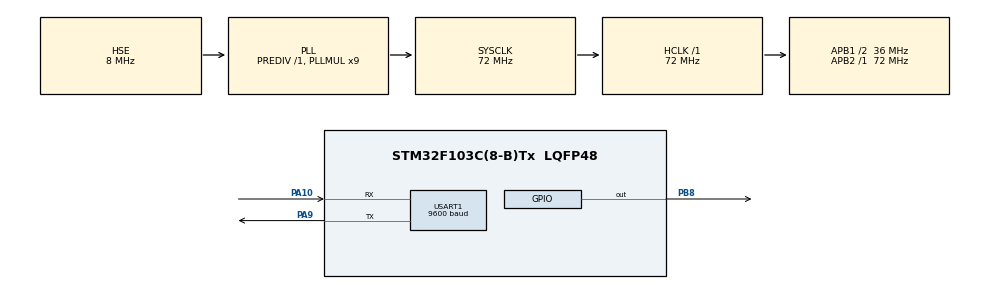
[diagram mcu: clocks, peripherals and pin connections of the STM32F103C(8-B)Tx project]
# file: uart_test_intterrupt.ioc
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Mcu.Family=STM32F1
Mcu.Name=STM32F103C(8-B)Tx
Mcu.Package=LQFP48
NVIC.PriorityGroup=NVIC_PRIORITYGROUP_4
NVIC.USART1_IRQn=true\:0\:0\:false\:false\:true\:true\:true\:true
PA10.Mode=Asynchronous
PA10.Signal=USART1_RX
PA9.Mode=Asynchronous
PA9.Signal=USART1_TX
PB8.PinState=GPIO_PIN_SET
PB8.Signal=GPIO_Output
PD0-OSC_IN.Mode=HSE-External-Oscillator
PD0-OSC_IN.Signal=RCC_OSC_IN
PD1-OSC_OUT.Mode=HSE-External-Oscillator
PD1-OSC_OUT.Signal=RCC_OSC_OUT
ProjectManager.HeapSize=0x200
ProjectManager.StackSize=0x400
ProjectManager.TargetToolchain=MDK-ARM V5.32
RCC.AHBFreq_Value=72000000
RCC.APB1CLKDivider=RCC_HCLK_DIV2
RCC.APB1Freq_Value=36000000
RCC.APB1TimFreq_Value=72000000
RCC.APB2Freq_Value=72000000
RCC.APB2TimFreq_Value=72000000
RCC.HCLKFreq_Value=72000000
RCC.PLLMUL=RCC_PLL_MUL9
RCC.PLLSourceVirtual=RCC_PLLSOURCE_HSE
RCC.SYSCLKFreq_VALUE=72000000
RCC.SYSCLKSource=RCC_SYSCLKSOURCE_PLLCLK
RCC.USBFreq_Value=72000000
USART1.BaudRate=9600
USART1.VirtualMode=VM_ASYNC
VP_SYS_VS_ND.Mode=No_Debug
board=custom

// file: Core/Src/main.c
/* USER CODE BEGIN Header */
/**
  ******************************************************************************
  * @file           : main.c
  * @brief          : Main program body
  ******************************************************************************
  * @attention
  *
  * Copyright (c) 2023 STMicroelectronics.
  * All rights reserved.
  *
  * This software is licensed under terms that can be found in the LICENSE file
  * in the root directory of this software component.
  * If no LICENSE file comes with this software, it is provided AS-IS.
  *
  ******************************************************************************
  */
/* USER CODE END Header */
#include "main.h"
#include "usart.h"
#include "gpio.h"

/* USER CODE BEGIN Includes */
#include <string.h>
#include <stdio.h>
/* USER CODE END Includes */

/* USER CODE BEGIN PM */
//定义最大接收字节数 200，可根据需求调整
#define UART1_REC_LEN 200
/* USER CODE END PM */

/* USER CODE BEGIN PV */
uint16_t UART1_RX_STA=0;
uint8_t buf=0;
// 接收缓冲, 串口接收到的数据放在这个数组里，最大UART1_REC_LEN个字节
uint8_t UART1_RX_Buffer[UART1_REC_LEN];
/* USER CODE END PV */

void SystemClock_Config(void);
/* USER CODE BEGIN PFP */

// 接收中断
void HAL_UART_RxCpltCallback(UART_HandleTypeDef *huart) {
	if(huart->Instance != USART1) {
		return;
	}
	// 数据接收完成
	if((UART1_RX_STA & 0x8000) != 0) {
		HAL_UART_Receive_IT(&huart1, &buf, 1);
		return;
	}
	// 接收到回车之后判断后续的是不是换行，如果是换行，数据接收完成，但是还要开启一下中断
	if(UART1_RX_STA&0x4000) {
		UART1_RX_STA= (buf == 0x0a) ? (UART1_RX_STA| 0x8000) : 0;
	} else {
		// 接收到回车，将高第二位置1，否则继续接收数据
		if(buf == 0x0d) {
			UART1_RX_STA |= 0x4000;
		} else {
			UART1_RX_Buffer[UART1_RX_STA&0x3fff] = buf;
			UART1_RX_STA ++;
			if(UART1_RX_STA > UART1_REC_LEN - 1) {
				UART1_RX_STA = 0;
			}
		}
	}
	HAL_UART_Receive_IT(&huart1, &buf, 1);
}
/* USER CODE END PFP */

/* USER CODE BEGIN 0 */
int fputc(int ch, FILE *file) {
	unsigned char temp[1] = {ch};
	HAL_UART_Transmit(&huart1, temp, 1, 0xfff);
	return ch;
}
/* USER CODE END 0 */

int main(void)
{

  /* MCU Configuration--------------------------------------------------------*/

  /* Reset of all peripherals, Initializes the Flash interface and the Systick. */
  HAL_Init();

  /* Configure the system clock */
  SystemClock_Config();

  /* Initialize all configured peripherals */
  MX_GPIO_Init();
  MX_USART1_UART_Init();
	HAL_UART_Receive_IT(&huart1, &buf, 1);
  /* Infinite loop */
  while (1)
  {
		if(UART1_RX_STA & 0x8000)
		{
			printf("收到数据：");
			if(UART1_RX_Buffer[0] == '\0') continue;
			if(!strcmp((const char *)UART1_RX_Buffer, "open")) {
				HAL_GPIO_WritePin(GPIOB, GPIO_PIN_8, GPIO_PIN_RESET);
			} else if(!strcmp((const char *)UART1_RX_Buffer, "close")){
				HAL_GPIO_WritePin(GPIOB, GPIO_PIN_8, GPIO_PIN_SET);
			} else {
				printf("error code");
			}
			HAL_UART_Transmit(&huart1, UART1_RX_Buffer, UART1_RX_STA & 0x3fff, 0xffff);
			while(huart1.gState != HAL_UART_STATE_READY);
			UART1_RX_STA = 0;
			/*
			// 将收到的数据发送到串口
			HAL_UART_Transmit(&huart1, UART1_RX_Buffer, UART1_RX_STA & 0x3fff, 0xffff);
			// 等待发送完成
			while(huart1.gState != HAL_UART_STATE_READY);
			printf("\r\n");
			// 重新开始下一次接收
			UART1_RX_STA = 0;
			*/
		} else {
			printf("hello heart\r\n");
		}
		HAL_Delay(1000);
  }
}

void SystemClock_Config(void)
{
  RCC_OscInitTypeDef RCC_OscInitStruct = {0};
  RCC_ClkInitTypeDef RCC_ClkInitStruct = {0};

  /** Initializes the RCC Oscillators according to the specified parameters
  * in the RCC_OscInitTypeDef structure.
  */
  RCC_OscInitStruct.OscillatorType = RCC_OSCILLATORTYPE_HSE;
  RCC_OscInitStruct.HSEState = RCC_HSE_ON;
  RCC_OscInitStruct.HSEPredivValue = RCC_HSE_PREDIV_DIV1;
  RCC_OscInitStruct.HSIState = RCC_HSI_ON;
  RCC_OscInitStruct.PLL.PLLState = RCC_PLL_ON;
  RCC_OscInitStruct.PLL.PLLSource = RCC_PLLSOURCE_HSE;
  RCC_OscInitStruct.PLL.PLLMUL = RCC_PLL_MUL9;
  if (HAL_RCC_OscConfig(&RCC_OscInitStruct) != HAL_OK)
  {
    Error_Handler();
  }

  /** Initializes the CPU, AHB and APB buses clocks
  */
  RCC_ClkInitStruct.ClockType = RCC_CLOCKTYPE_HCLK|RCC_CLOCKTYPE_SYSCLK
                              |RCC_CLOCKTYPE_PCLK1|RCC_CLOCKTYPE_PCLK2;
  RCC_ClkInitStruct.SYSCLKSource = RCC_SYSCLKSOURCE_PLLCLK;
  RCC_ClkInitStruct.AHBCLKDivider = RCC_SYSCLK_DIV1;
  RCC_ClkInitStruct.APB1CLKDivider = RCC_HCLK_DIV2;
  RCC_ClkInitStruct.APB2CLKDivider = RCC_HCLK_DIV1;

  if (HAL_RCC_ClockConfig(&RCC_ClkInitStruct, FLASH_LATENCY_2) != HAL_OK)
  {
    Error_Handler();
  }
}

void Error_Handler(void)
{
  __disable_irq();
  while (1)
  {
  }
}
